# BL808 register map
File version: 0.1
Registers are access not given, no defined reset value unless marked. A register's access mark holds for its fields unless they carry their own. Offsets are from the block's base; [hi:lo] are bit positions.

## SDH (part 2 of 2)
Base 0x20060000
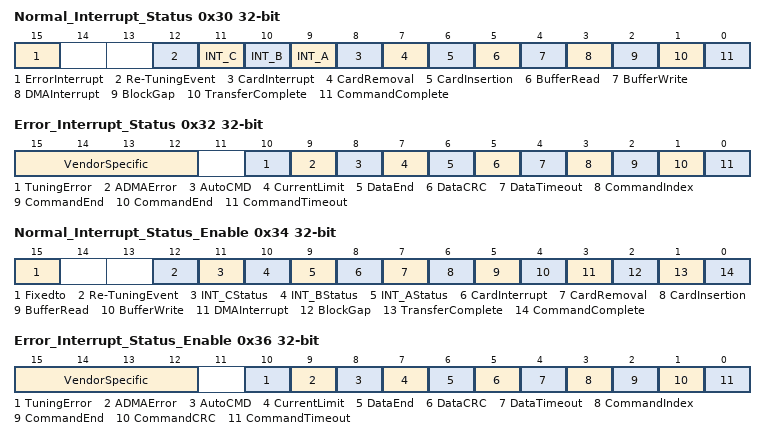
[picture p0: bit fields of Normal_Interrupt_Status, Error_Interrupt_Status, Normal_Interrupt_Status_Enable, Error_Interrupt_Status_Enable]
0x30 Normal_Interrupt_Status
  [15] ErrorInterrupt ro — Error Interrupt If any of the bits in the Error Interrupt Status register are set, then this bit is set. Therefore the Host Driver can efficiently test for an error by checking this bit first. This bit is read only.
  [12] Re-TuningEvent ro — Re-Tuning Event This status is set if Re-Tuning Request in the Present State register changes from 0 to 1. Host Controller requests Host Driver to perform re-tuning for next data transfer. Current data transfer (not large block count) can be completed without re-tuning.
  [11] INT_C ro — INT_C This status is set if INT_C is enabled and INT_C# pin is in low level. Writing this bit to 1 does not clear this bit. It is cleared by resetting the INT_C interrupt factor. Refer to the Shared Bus Control register.
  [10] INT_B ro — INT_B This status is set if INT_B is enabled and INT_B# pin is in low level. Writing this bit to 1 does not clear this bit. It is cleared by resetting the INT_B interrupt factor. Refer to the Shared Bus Control register.
  [9] INT_A ro — INT_A This status is set if INT_A is enabled and INT_A# pin is in low level. Writing this bit to 1 does not clear this bit. It is cleared by resetting the INT_A interrupt factor. Refer to the Shared Bus Control register.
  [8] CardInterrupt ro — Card Interrupt Writing this bit to 1 does not clear this bit. It is cleared by resetting the SD card interrupt factor. In 1-bit mode, the Host Controller shall detect the Card Interrupt without SD Clock to support wakeup. In 4-bit mode, the card interrupt signal is sampled during the interrupt cycle, so there are some sample delays between the interrupt signal from the SD card and the interrupt to the Host System. When this status has been set and the Host Driver needs to start this interrupt service, Card Interrupt Status Enable in the Normal Interrupt Status Enable register may be set to 0 in order to clear the card interrupt statuses latched in the Host Controller and to stop driving the interrupt signal to the Host System. After completion of the card interrupt service (It should reset interrupt factors in the SD card and the interrupt signal may not be asserted), set Card Interrupt Status Enable to 1 and start sampling the interrupt signal again. Interrupt detected by DAT[1] is supported when there is a card per slot. In case of shared bus, interrupt pins are used to detect interrupts. If 000b is set to Interrupt Pin Select in the Shared Bus Control register, this status is effective. Non-zero value is set to Interrupt Pin Select, INT_A, INT_B or INT_C is then used to device interrupts.
  [7] CardRemoval rw — Card Removal This status is set if the Card Inserted in the Present State register changes from 1 to 0. When the Host Driver writes this bit to 1 to clear this status, the status of the Card Inserted in the Present State register should be confirmed. Because the card detect state may possibly be changed when the Host Driver clear this bit and interrupt event may not be generated.
  [6] CardInsertion rw — Card Insertion This status is set if the Card Inserted in the Present State register changes from 0 to 1. When the Host Driver writes this bit to 1 to clear this status, the status of the Card Inserted in the Present State register should be confirmed. Because the card detect state may possibly be changed when the Host Driver clear this bit and interrupt event may not be generated.
  [5] BufferRead rw — Buffer Read Ready This status is set if the Buffer Read Enable changes from 0 to 1. Refer to the Buffer Read Enable in the Present State register. While performing tuning procedure (Execute Tuning is set to 1), Buffer Read Ready is set to 1 for every CMD19 execution.
  [4] BufferWrite rw — Buffer Write Ready This status is set if the Buffer Write Enable changes from 0 to 1. Refer to the Buffer Write Enable in the Present State register.
  [3] DMAInterrupt rw — DMA Interrupt This status is set if the Host Controller detects the Host SDMA Buffer boundary during transfer. Refer to the Host SDMA Buffer Boundary in the Block Size register. Other DMA interrupt factors may be added in the future. In case of ADMA, by setting Int field in the descriptor table, Host Controller generates this interrupt. Suppose that it is used for debugging. This interrupt shall not be generated after the Transfer Complete.
  [2] BlockGap rw — Block Gap Event If the Stop At Block Gap Request in the Block Gap Control register is set, this bit is set when both a read / write transaction is stopped at a block gap. If Stop At Block Gap Request is not set to 1, this bit is not set to 1. (1) In the case of a Read Transaction This bit is set at the falling edge of the DAT Line Active Status (When the transaction is stopped at SD Bus timing. The Read Wait shall be supported in order to use this function. Refer to Section 3.12.3 about the detail timing. (2) Case of Write Transaction This bit is set at the falling edge of Write Transfer Active Status (After getting CRC status at SD Bus timing). Refer to Section 3.12.4 for more details on the sequence of events.
  [1] TransferComplete rw — Transfer Complete This bit is set when a read / write transfer and a command with busy is completed. (1) In the case of a Read Transaction This bit is set at the falling edge of Read Transfer Active Status. This interrupt is generated in two cases. The first is when a data transfer is completed as specified by data length (After the last data has been read to the Host System). The second is when data has stopped at the block gap and completed the data transfer by setting the Stop At Block Gap Request in the Block Gap Control register (After valid data has been read to the Host System). (2) In the case of a Write Transaction This bit is set at the falling edge of the DAT Line Active Status. This interrupt is generated in two cases. The first is when the last data is written to the SD card as specified by data length and the busy signal released. The second is when data transfers are stopped at the block gap by setting Stop At Block Gap Request in the Block Gap Control register and data transfers completed. (After valid data is written to the SD card and the busy signal released). (3) In the case of a command with busy This bit is set when busy is de-asserted. Refer to DAT Line Active and Command Inhibit (DAT) in the Present State register.
  [0] CommandComplete rw — Command Complete This bit is set when get the end bit of the command response. Auto CMD12 and Auto CMD23 consist of two responses. Command Complete is not generated by the response of CMD12 or CMD23 but generated by the response of a read/write command. Refer to Command Inhibit (CMD) in the Present State register for how to control this bit. The table below shows that Command Timeout Error has higher priority than Command Complete. If both bits are set to 1, it can be considered that the response was not received correctly.
0x32 Error_Interrupt_Status
  [15:12] VendorSpecific rw — Vendor Specific Error Status Additional status bits can be defined in this register by the vendor.
  [10] TuningError rw — Tuning Error This bit is set when an unrecoverable error is detected in a tuning circuit except during tuning procedure (Occurrence of an error during tuning procedure is indicated by Sampling Select). By detecting Tuning Error, Host Driver needs to abort a command executing and perform tuning. To reset tuning circuit, Sampling Clock shall be set to 0 before executing tuning procedure . The Tuning Error is higher priority than the other error interrupts generated during data transfer. By detecting Tuning Error, the Host Driver should discard data transferred by a current read/write command and retry data transfer after the Host Controller retrieved from tuning circuit error.
  [9] ADMAError rw — ADMA Error This bit is set when the Host Controller detects errors during ADMA based data transfer. The state of the ADMA at an error occurrence is saved in the ADMA Error Status Register, In addition, the Host Controller generates this Interrupt when it detects invalid descriptor data (Valid=0) at the ST_FDS state. ADMA Error State in the ADMA Error Status indicates that an error occurs in ST_FDS state. The Host Driver may find that Valid bit is not set at the error descriptor.
  [8] AutoCMD rw — Auto CMD Error Auto CMD12 and Auto CMD23 use this error status. This bit is set when detecting that one of the bits D00-D04 in Auto CMD Error Status register has changed from 0 to 1. In case of Auto CMD12, this bit is set to 1, not only when the errors in Auto CMD12 occur but also when Auto CMD12 is not executed due to the previous command error.
  [7] CurrentLimit rw — Current Limit Error By setting the SD Bus Power bit in the Power Control register, the Host Controller is requested to supply power for the SD Bus. If the Host Controller supports the Current Limit function, it can be protected from an illegal card by stopping power supply to the card in which case this bit indicates a failure status. Reading 1 means the Host Controller is not supplying power to SD card due to some failure. Reading 0 means that the Host Controller is supplying power and no error has occurred. The Host Controller may require some sampling time to detect the current limit. If the Host Controller does not support this function, this bit shall always be set to 0.
  [6] DataEnd rw — Data End Bit Error Occurs either when detecting 0 at the end bit position of read data which uses the DAT line or at the end bit position of the CRC Status.
  [5] DataCRC rw — Data CRC Error Occurs when detecting CRC error when transferring read data which uses the DAT line or when detecting the Write CRC status having a value of other than "010".
  [4] DataTimeout rw — Data Timeout Error This bit is set when detecting one of following timeout conditions. (1) Busy timeout for R1b,R5b type (2) Busy timeout after Write CRC status (3) Write CRC Status timeout (4) Read Data timeout.
  [3] CommandIndex rw — Command Index Error This bit is set if a Command Index error occurs in the command response.
  [2] CommandEnd rw — Command End Bit Error This bit is set when detecting that the end bit of a command response is 0.
  [1] CommandEnd rw — Command CRC Error Command CRC Error is generated in two cases. If a response is returned and the Command Timeout Error is set to 0 (indicating no timeout), this bit is set to 1 when detecting a CRC error in the command response. The Host Controller detects a CMD line conflict by monitoring the CMD line when a command is issued. If the Host Controller drives the CMD line to 1 level, but detects 0 level on the CMD line at the next SD clock edge, then the Host Controller shall abort the command (Stop driving CMD line) and set this bit to 1. The Command Timeout Error shall also be set to 1 to distinguish CMD line conflict .
  [0] CommandTimeout rw — Command Timeout Error This bit is set only if no response is returned within 64 SD clock cycles from the end bit of the command.
0x34 Normal_Interrupt_Status_Enable
  [15] Fixedto ro — Fixed to 0 The Host Driver shall control error interrupts using the Error Interrupt Status Enable register.
  [12] Re-TuningEvent rw — Re-Tuning Event Status Enable 1 Enabled 0 Masked
  [11] INT_CStatus rw — INT_C Status Enable If this bit is set to 0, the Host Controller shall clear the interrupt request to the System. The Host Driver may clear this bit before servicing the INT_C and may set this bit again after all interrupt requests to INT_C pin are cleared to prevent inadvertent interrupts.
  [10] INT_BStatus rw — INT_B Status Enable If this bit is set to 0, the Host Controller shall clear the interrupt request to the System. The Host Driver may clear this bit before servicing the INT_B and may set this bit again after all interrupt requests to INT_B pin are cleared to prevent inadvertent interrupts.
  [9] INT_AStatus rw — INT_A Status Enable If this bit is set to 0, the Host Controller shall clear the interrupt request to the System. The Host Driver may clear this bit before servicing the INT_A and may set this bit again after all interrupt requests to INT_A pin are cleared to prevent inadvertent interrupts.
  [8] CardInterrupt rw — If this bit is set to 0, the Host Controller shall clear interrupt request to the System. The Card Interrupt detection is stopped when this bit is cleared and restarted when this bit is set to 1. The Host Driver may clear the Card Interrupt Status Enable before servicing the Card Interrupt and may set this bit again after all interrupt requests from the card are cleared to prevent inadvertent interrupts.
  [7] CardRemoval rw — Card Removal Status Enable
  [6] CardInsertion rw — Card Insertion Status Enable
  [5] BufferRead rw — Buffer Read Ready Status Enable
  [4] BufferWrite rw — Buffer Write Ready Status Enable
  [3] DMAInterrupt rw — DMA Interrupt Status Enable
  [2] BlockGap rw — Block Gap Event Status Enable
  [1] TransferComplete rw — Transfer Complete Status Enable
  [0] CommandComplete rw — Command Complete Status Enable
0x36 Error_Interrupt_Status_Enable
  [15:12] VendorSpecific rw — Vendor Specific Error Status Enable
  [10] TuningError rw — Tuning Error Status Enable
  [9] ADMAError rw — ADMA Error Status Enable
  [8] AutoCMD rw — Auto CMD Error Status Enable
  [7] CurrentLimit rw — Current Limit Error Status Enable
  [6] DataEnd rw — Data End Bit Error Status Enable
  [5] DataCRC rw — Data CRC Error Status Enable
  [4] DataTimeout rw — Data Timeout Error Status Enable
  [3] CommandIndex rw — Command Index Error Status Enable
  [2] CommandEnd rw — Command End Bit Error Status Enable
  [1] CommandCRC rw — Command CRC Error Status Enable
  [0] CommandTimeout rw — Command Timeout Error Status Enable
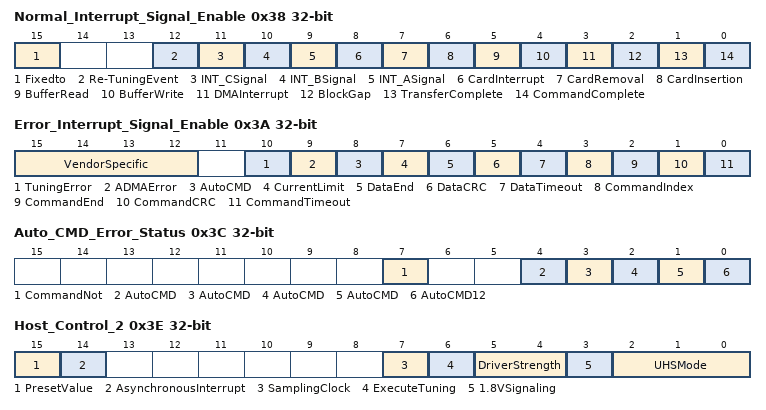
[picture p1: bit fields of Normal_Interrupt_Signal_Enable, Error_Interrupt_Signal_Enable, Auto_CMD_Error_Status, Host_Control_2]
0x38 Normal_Interrupt_Signal_Enable
  [15] Fixedto ro — Fixed to 0 The Host Driver shall control error interrupts using the Error Interrupt Signal Enable register.
  [12] Re-TuningEvent rw — Re-Tuning Event Signal Enable
  [11] INT_CSignal rw — INT_C Signal Enable
  [10] INT_BSignal rw — INT_B Signal Enable
  [9] INT_ASignal rw — INT_A Signal Enable
  [8] CardInterrupt rw — Card Interrupt Signal Enable
  [7] CardRemoval rw — Card Removal Signal Enable
  [6] CardInsertion rw — Card Insertion Signal Enable
  [5] BufferRead rw — Buffer Read Ready Signal Enable
  [4] BufferWrite rw — Buffer Write Ready Signal Enable
  [3] DMAInterrupt rw — DMA Interrupt Signal Enable
  [2] BlockGap rw — Block Gap Event Signal Enable
  [1] TransferComplete rw — Transfer Complete Signal Enable
  [0] CommandComplete rw — Command Complete Signal Enable
0x3A Error_Interrupt_Signal_Enable
  [15:12] VendorSpecific rw — Vendor Specific Error Signal Enable
  [10] TuningError rw — Tuning Error Signal Enable
  [9] ADMAError rw — ADMA Error Signal Enable
  [8] AutoCMD rw — Auto CMD Error Signal Enable
  [7] CurrentLimit rw — Current Limit Error Signal Enable
  [6] DataEnd rw — Data End Bit Error Signal Enable
  [5] DataCRC rw — Data CRC Error Signal Enable
  [4] DataTimeout rw — Data Timeout Error Signal Enable
  [3] CommandIndex rw — Command Index Error Signal Enable
  [2] CommandEnd rw — Command End Bit Error Signal Enable
  [1] CommandCRC rw — Command CRC Error Signal Enable
  [0] CommandTimeout rw — Command Timeout Error Signal Enable
0x3C Auto_CMD_Error_Status
  [7] CommandNot ro — Command Not Issued By Auto CMD12 Error Setting this bit to 1 means CMD_wo_DAT is not executed due to an Auto CMD12 Error (D04-D01) in this register. This bit is set to 0 when Auto CMD Error is generated by Auto CMD23.
  [4] AutoCMD ro — Auto CMD Index Error This bit is set if the Command Index error occurs in response to a command.
  [3] AutoCMD ro — Auto CMD End Bit Error This bit is set when detecting that the end bit of command response is 0.
  [2] AutoCMD ro — Auto CMD CRC Error
  [1] AutoCMD ro — Auto CMD Timeout Error
  [0] AutoCMD12 ro — Auto CMD12 Not Executed
0x3E Host_Control_2
  [15] PresetValue rw — Preset Value Enable Host Controller Version 3.00 supports this bit. As the operating SDCLK frequency and I/O driver strength depend on the Host System implementation, it is difficult to determine these parameters in the Standard Host Driver. When Preset Value Enable is set, automatic SDCLK frequency generation and driver strength selection is performed without considering system specific conditions. This bit enables the functions defined in the Preset Value registers.
  [14] AsynchronousInterrupt rw — Asynchronous Interrupt Enable This bit can be set to 1 if a card supports asynchronous interrupts and Asynchronous Interrupt Support is set to 1 in the Capabilities register. Asynchronous interrupt is effective when DAT[1] interrupt is used in 4-bit SD mode (and zero is set to Interrupt Pin Select in the Shared Bus Control register). If this bit is set to 1, the Host Driver can stop the SDCLK during asynchronous interrupt period to save power. During this period, the Host Controller continues to deliver the Card Interrupt to the host when it is asserted by the Card.
  [7] SamplingClock rw — Sampling Clock Select Host Controller uses this bit to select sampling clock to receive CMD and DAT. This bit is set by tuning procedure and valid after the completion of tuning (when Execute Tuning is cleared). Setting 1 means that tuning is completed successfully and setting 0 means that tuning is failed. Writing 1 to this bit is meaningless and ignored. A tuning circuit is reset by writing to 0. This bit can be cleared with setting Execute Tuning. Once the tuning circuit is reset, it will take time to complete tuning sequence. Therefore, Host Driver should keep this bit to 1 to perform re-tuning sequence to compete re-tuning sequence in a short time. Change of this bit is not allowed while the Host Controller is receiving response or a read data block.
  [6] ExecuteTuning rw — Execute Tuning This bit is set to 1 to start tuning procedure and automatically cleared when tuning procedure is completed. The result of tuning is indicated to Sampling Clock Select. Tuning procedure is aborted by writing 0. Refer to Figure 2-29 for more detail about tuning procedure.
  [5:4] DriverStrength rw — Driver Strength Select Host Controller output driver in 1.8V signaling is selected by this bit. In 3.3V signaling, this field is not effective. This field can be set depends on Driver Type A, C and D support bits in the Capabilities register. This bit depends on setting of Preset Value Enable. If Preset Value Enable = 0, this field is set by Host Driver. If Preset Value Enable = 1, this field is automatically set by a value specified in the one of Preset Value registers.
  [3] 1.8VSignaling rw — 1.8V Signaling Enable This bit controls voltage regulator for I/O cell. 3.3V is supplied to the card regardless of signaling voltage. Setting this bit from 0 to 1 starts changing signal voltage from 3.3V to 1.8V. 1.8V regulator output shall be stable within 5ms. Host Controller clears this bit if switching to 1.8V signaling fails. Clearing this bit from 1 to 0 starts changing signal voltage from 1.8V to 3.3V. 3.3V regulator output shall be stable within 5ms. Host Driver can set this bit to 1 when Host Controller supports 1.8V signaling (One of support bits is set to 1: SDR50, SDR104 or DDR50 in the Capabilities register) and the card or device supports UHS-I (S18A=1. Refer to Bus Signal Voltage Switch Sequence in the Physical Layer Specification Version 3.0x).
  [2:0] UHSMode rw — UHS Mode Select This field is used to select one of UHS-I modes and effective when 1.8V Signaling Enable is set to 1.
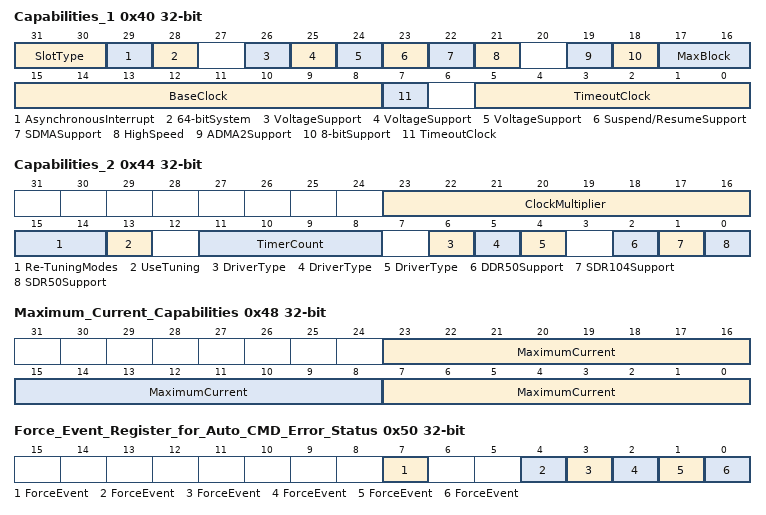
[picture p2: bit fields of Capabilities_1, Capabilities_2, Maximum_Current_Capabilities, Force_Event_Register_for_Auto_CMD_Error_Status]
0x40 Capabilities_1
  [31:30] SlotType ro — Slot Type This field indicates usage of a slot by a specific Host System. (A host controller register set is defined per slot.) Embedded Slot for One Device (01b) means that only one non-removable device is connected to a SD bus slot. Shared Bus Slot (10b) can be set if Host Controller supports Shared Bus Control register. The Standard Host Driver controls only a removable card or one embedded device connected to a SD bus slot. If a slot is configured for shared bus (10b), the Standard Host Driver does not control embedded devices connected to a shared bus. Shared bus slot is controlled by a specific host driver developed by a Host System. 00b Removable Card Slot 01b Embedded Slot for One Device 10b Shared Bus Slot 11b Reserved
  [29] AsynchronousInterrupt ro — Asynchronous Interrupt Support Refer to SDIO Specification Version 3.00 about asynchronous interrupt.
  [28] 64-bitSystem ro — 64-bit System Bus Support Setting 1 to this bit indicates that the Host Controller supports 64-bit address descriptor mode and is connected to 64-bit address system bus.
  [26] VoltageSupport ro — Voltage Support 1.8V Embedded system can use 1.8V power supply.
  [25] VoltageSupport ro — Voltage Support 3.0V 1 :3.0V Supported 0 :3.0V Not Supported
  [24] VoltageSupport ro — Voltage Support 3.3V
  [23] Suspend/ResumeSupport ro — Suspend/Resume Support This bit indicates whether the Host Controller supports Suspend / Resume functionality. If this bit is 0, the Host Driver shall not issue either Suspend or Resume commands because the Suspend and Resume mechanism is not supported.
  [22] SDMASupport ro — SDMA Support This bit indicates whether the Host Controller is capable of using SDMA to transfer data between system memory and the Host Controller directly.
  [21] HighSpeed ro — High Speed Support This bit indicates whether the Host Controller and the Host System support High Speed mode and they can supply SD Clock frequency from 25MHz to 50MHz.
  [19] ADMA2Support ro — ADMA2 Support This bit indicates whether the Host Controller is capable of using ADMA2.
  [18] 8-bitSupport ro — 8-bit Support for Embedded Device This bit indicates whether the Host Controller is capable of using 8-bit bus width mode. This bit is not effective when Slot Type is set to 10b. In this case, refer to Bus Width Preset in the Shared Bus resister.
  [17:16] MaxBlock ro — Max Block Length This value indicates the maximum block size that the Host Driver can read and write to the buffer in the Host Controller. The buffer shall transfer this block size without wait cycles. Three sizes can be defined as indicated below. It is noted that transfer block length shall be always 512 bytes for SD Memory Cards regardless this field.
  [15:8] BaseClock ro — Base Clock Frequency For SD Clock This value indicates the base (maximum) clock frequency for the SD Clock. Definition of this field depends on Host Controller Version.
  [7] TimeoutClock ro — Timeout Clock Unit This bit shows the unit of base clock frequency used to detect Data Timeout Error.
  [5:0] TimeoutClock ro — Timeout Clock Frequency This bit shows the base clock frequency used to detect Data Timeout Error. The Timeout Clock Unit defines the unit of this field's value.
0x44 Capabilities_2
  [23:16] ClockMultiplier ro — Clock Multiplier This field indicates clock multiplier value of programmable clock generator. Refer to Clock Control register. Setting 00h means that Host Controller does not support programmable clock generator.
  [15:14] Re-TuningModes ro — Re-Tuning Modes This field selects re-tuning method and limits the maximum data length.
  [13] UseTuning ro — Use Tuning for SDR50 If this bit is set to 1, this Host Controller requires tuning to operate SDR50. (Tuning is always required to operate SDR104.)
  [11:8] TimerCount ro — Timer Count for Re-Tuning This field indicates an initial value of the Re-Tuning Timer for Re-Tuning Mode 1 to 3. Setting to 0 disables Re-Tuning Timer.
  [6] DriverType ro — Driver Type D Support This bit indicates support of Driver Type D for 1.8 Signaling.
  [5] DriverType ro — Driver Type C Support This bit indicates support of Driver Type C for 1.8 Signaling.
  [4] DriverType ro — Driver Type A Support This bit indicates support of Driver Type A for 1.8 Signaling.
  [2] DDR50Support ro
  [1] SDR104Support ro — SDR104 Support SDR104 requires tuning.
  [0] SDR50Support ro — SDR50 Support If SDR104 is supported, this bit shall be set to 1. Bit 45 indicates whether SDR50 requires tuning or not.
0x48 Maximum_Current_Capabilities
  [23:16] MaximumCurrent ro — Maximum Current for 1.8V
  [15:8] MaximumCurrent ro — Maximum Current for 3.0V
  [7:0] MaximumCurrent ro — Maximum Current for 3.3V
0x50 Force_Event_Register_for_Auto_CMD_Error_Status
  [7] ForceEvent wo — Force Event for Command Not Issued By Auto CMD12 Error
  [4] ForceEvent wo — Force Event for Auto CMD Index Error
  [3] ForceEvent wo — Force Event for Auto CMD End Bit Error
  [2] ForceEvent wo — Force Event for Auto CMD CRC Error
  [1] ForceEvent wo — Force Event for Auto CMD Timeout Error
  [0] ForceEvent wo — Force Event for Auto CMD12 Not Executed
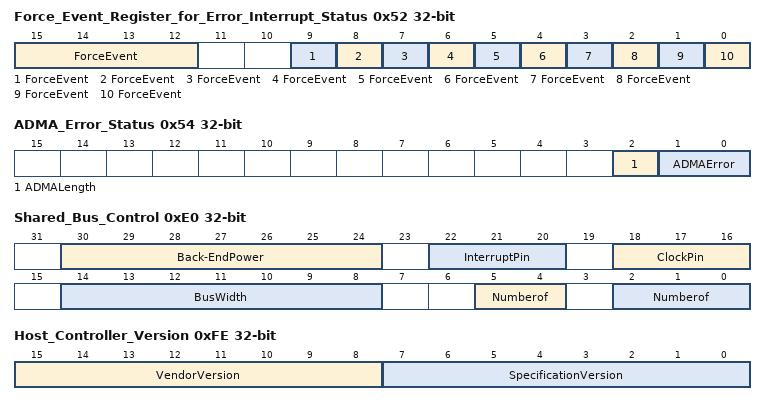
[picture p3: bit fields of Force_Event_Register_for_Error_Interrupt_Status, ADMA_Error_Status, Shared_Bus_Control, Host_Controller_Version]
0x52 Force_Event_Register_for_Error_Interrupt_Status
  [15:12] ForceEvent wo — Force Event for Vendor Specific Error Status Additional status bits can be defined in this register by the vendor.
  [9] ForceEvent wo — Force Event for ADMA Error
  [8] ForceEvent wo — Force Event for Auto CMD Error
  [7] ForceEvent wo — Force Event for Current Limit Error
  [6] ForceEvent wo — Force Event for Data End Bit Error
  [5] ForceEvent wo — Force Event for Data CRC Error
  [4] ForceEvent wo — Force Event for Data Timeout Error
  [3] ForceEvent wo — Force Event for Command Index Error
  [2] ForceEvent wo — Force Event for Command End Bit Error
  [1] ForceEvent wo — Force Event for Command CRC Error
  [0] ForceEvent wo — Force Event for Command Timeout Error
0x54 ADMA_Error_Status
  [2] ADMALength ro — ADMA Length Mismatch Error This error occurs in the following 2 cases. (1) While Block Count Enable being set, the total data length specified by the Descriptor table is different from that specified by the Block Count and Block Length. (2) Total data length can not be divided by the block length.
  [1:0] ADMAError ro — ADMA Error State This field indicates the state of ADMA when error is occurred during ADMA data transfer. This field never indicates "10" because ADMA never stops in this state.
0xE0 Shared_Bus_Control
  [30:24] Back-EndPower rw — Back-End Power Control Each bit of this field controls back-end power supply for an embedded device. Host interface voltage (VDDH) is not controlled by this field. The number of devices supported is specified by Number of Clock Pins and a maximum of 7 devices can be controlled.
  [22:20] InterruptPin rw — Interrupt Pin Select Interrupt pin inputs are enabled by this field. Enable of unsupported interrupt pin is meaningless.
  [18:16] ClockPin rw — Clock Pin Select One of clock pin outputs is selected by this field. Select of unsupported clock pin is meaningless. Refer to Figure 2-38 for the timing of clock outputs.
  [14:8] BusWidth rw — Bus Width Preset Shared bus supports mixing of 4-bit and 8-bit bus width devices. Each bit of this field specifies the bus width for each embedded device. The number of devices supported is specified by Number of Clock Pins and a maximum of 7 devices are supported. This field is effective when multiple devices are connected to a shared bus (Slot Type is set to 10b in the Capabilities register). In the other case, Extended Data Transfer Width in the Host Control 1 register is used to select 8-bit bus width. As use of 1-bit mode is not intended for shared bus, Data Transfer Width in the Host Control 1 register should be set to 1.
  [5:4] Numberof rw — Number of Interrupt Input Pins This field indicates support of interrupt input pins for shared bus system. Three asynchronous interrupt pins are defined, INT_A#, INT_B# and INT_C#. Which interrupt pin is used is determined by the system. Each one is driven by open drain and then wired or connection is possible.
  [2:0] Numberof ro — Number of Clock Pins This field indicates support of clock pins to select one of devices for shared bus system. Up to 7 clock pins can be supported. Shared bus is supported by specific system. Then Standard Host Driver does not support control of these clock pins.
0xFC Slot_Interrupt_Status
  [7:0] InterruptSignal ro — Interrupt Signal For Each Slot These status bits indicate the logical OR of Interrupt Signal and Wakeup Signal for each slot. A maximum of 8 slots can be defined. If one interrupt signal is associated with multiple slots, the Host Driver can know which interrupt is generated by reading these status bits. By a power on reset or by setting Software Reset For All, the interrupt signal shall be de-asserted and this status shall read 00h.
0xFE Host_Controller_Version
  [15:8] VendorVersion ro — Vendor Version Number This status is reserved for the vendor version number. The Host Driver should not use this status.
  [7:0] SpecificationVersion ro — Specification Version Number This status indicates the Host Controller Spec. Version. The upper and lower 4-bits indicate the version. 00h SD Host Specification Version 1.00 01h SD Host Specification Version 2.00 Including the feature of the ADMA and Test Register, 02h SD Host Specification Version 3.00 others Reserved
